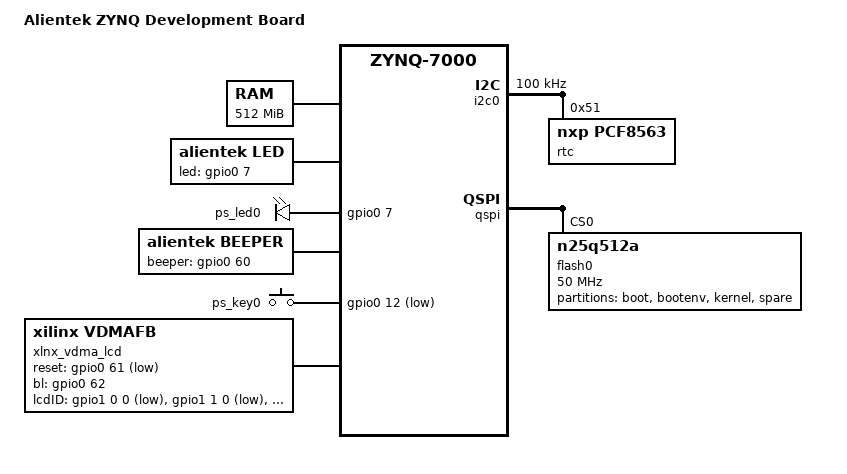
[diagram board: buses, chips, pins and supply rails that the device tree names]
/*
 * CAUTION: This file is automatically generated by Xilinx.
 * Version: HSI 
 * Today is: Wed Jul 22 03:39:39 2020
 */

#define GPIO_ACTIVE_HIGH   0
#define GPIO_ACTIVE_LOW    1

/dts-v1/;
#include "zynq-7000.dtsi"
#include "pl.dtsi"
#include "pcw.dtsi"
#include <dt-bindings/interrupt-controller/irq.h>
#include <dt-bindings/input/linux-event-codes.h>
/ {
	model = "Alientek ZYNQ Development Board";

	chosen {
		bootargs = "console=ttyPS0,115200 earlyprintk root=/dev/mmcblk0p2 rw rootwait";
		stdout-path = "serial0:115200n8";
	};
	aliases {
		ethernet0 = &gem0;
		ethernet1 = &gem1;
		i2c0 = &i2c0;
		i2c1 = &i2c1;
		i2c2 = &i2c2;
		serial0 = &uart0;
		serial1 = &uart1;
		spi0 = &qspi;
	};
	memory {
		device_type = "memory";
		reg = <0x0 0x20000000>;
	};

	led {
		compatible = "alientek,led";
		status = "okay";
		default-state = "on";
		led-gpio = <&gpio0 7 GPIO_ACTIVE_HIGH>;
	};

	user-leds {
		compatible = "gpio-leds";

		led@0 {
			label = "ps_led0";
			gpios = <&gpio0 7 GPIO_ACTIVE_HIGH>;
			default-state = "off";
		};
	};

	beeper {
		compatible = "alientek,beeper";
		status = "okay";
		default-state = "off";
		beeper-gpio = <&gpio0 60 GPIO_ACTIVE_HIGH>;
	};

	key {
		compatible = "gpio-keys";
		autorepeat;

		key@0 {
			label = "ps_key0";
			linux,code = <KEY_ENTER>;
			gpios = <&gpio0 12 GPIO_ACTIVE_LOW>;
			debounce-interval = <15>;
		};
	};
};

&i2c0 {
	clock-frequency = <100000>;

	rtc@51 {
		compatible = "nxp,pcf8563";
		reg = <0x51>;
	};
};

&gem0 {
	local-mac-address = [00 0a 35 00 1e 53];
};

&qspi {
	#address-cells = <1>;
	#size-cells = <0>;
	flash0: flash@0 {
		compatible = "n25q512a","micron,m25p80";
		reg = <0x0>;
		#address-cells = <1>;
		#size-cells = <1>;
		spi-max-frequency = <50000000>;
		partition@0x00000000 {
			label = "boot";
			reg = <0x00000000 0x00500000>;
		};
		partition@0x00500000 {
			label = "bootenv";
			reg = <0x00500000 0x00020000>;
		};
		partition@0x00520000 {
			label = "kernel";
			reg = <0x00520000 0x00a80000>;
		};
		partition@0x00fa0000 {
			label = "spare";
			reg = <0x00fa0000 0x00000000>;
		};
	};
};

&lcd_vtc {
	compatible = "xlnx,v-tc-5.01.a";
};

&amba_pl {
	xlnx_vdma_lcd {
		compatible = "xilinx,vdmafb";

		vtc = <&lcd_vtc>;
		clocks = <&clk_wiz_0 0>;
		clock-names = "lcd_pclk";
		dmas = <&lcd_vdma 0>;
		dma-names = "lcd_vdma";

		reset-gpio = <&gpio0 61 GPIO_ACTIVE_LOW>;
		bl-gpio = <&gpio0 62 GPIO_ACTIVE_HIGH>;
		lcdID-gpio = <&gpio1 0 0 GPIO_ACTIVE_LOW &gpio1 1 0 GPIO_ACTIVE_LOW &gpio1 2 0 GPIO_ACTIVE_LOW>;

		pixel-format = "RGB888";
		display-timings {
			timing_4342: timing0 {
				clock-frequency = <9000000>;
				hactive = <480>;
				vactive = <272>;
				hback-porch = <40>;
				hfront-porch = <5>;
				hsync-len = <1>;
				vback-porch = <8>;
				vfront-porch = <8>;
				vsync-len = <1>;
				hsync-active = <0>;
				vsync-active = <0>;
				de-active = <1>;
				pixelclk-active = <0>;
			};
			timing_4384: timing1 {
				clock-frequency = <31000000>;
				hactive = <800>;
				vactive = <480>;
				hback-porch = <88>;
				hfront-porch = <40>;
				hsync-len = <48>;
				vback-porch = <32>;
				vfront-porch = <13>;
				vsync-len = <3>;
				hsync-active = <0>;
				vsync-active = <0>;
				de-active = <1>;
				pixelclk-active = <0>;
			};
			timing_7084: timing2 {
				clock-frequency = <33300000>;
				hactive = <800>;
				vactive = <480>;
				hback-porch = <46>;
				hfront-porch = <210>;
				hsync-len = <1>;
				vback-porch = <23>;
				vfront-porch = <22>;
				vsync-len = <1>;
				hsync-active = <0>;
				vsync-active = <0>;
				de-active = <1>;
				pixelclk-active = <0>;
			};
			timing_7016: timing3 {
				clock-frequency = <51200000>;
				hactive = <1024>;
				vactive = <600>;
				hback-porch = <140>;
				hfront-porch = <160>;
				hsync-len = <20>;
				vback-porch = <20>;
				vfront-porch = <12>;
				vsync-len = <3>;
				hsync-active = <0>;
				vsync-active = <0>;
				de-active = <1>;
				pixelclk-active = <0>;
			};
			timing_1018: timing4 {
				clock-frequency = <71100000>;
				hactive = <1280>;
				vactive = <800>;
				hback-porch = <80>;
				hfront-porch = <70>;
				hsync-len = <10>;
				vback-porch = <10>;
				vfront-porch = <10>;
				vsync-len = <3>;
				hsync-active = <0>;
				vsync-active = <0>;
				de-active = <1>;
				pixelclk-active = <0>;
			};
		};
	};
};
